AUTOSAR XML (schema 4-3-0)
package /ComponentTypes
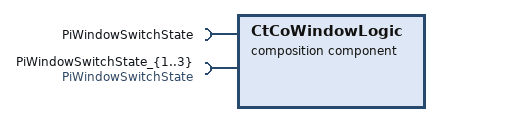
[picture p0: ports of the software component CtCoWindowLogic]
  composition sw component type CtCoWindowLogic
    4 x require port, all with required-com-specs=[data-element=DeWindowSwitchState, data-element=Element], required-interface=PiWindowSwitchState:
      PiWindowSwitchState
      PiWindowSwitchState_{1..3}
